# ATSAMD21E15BU register map
Vendor: Atmel Corporation; Series: SAMD21; File version: D
CPU: CM0+ r0p1, little endian, no MPU, no FPU, VTOR, 2 interrupt priority bits
Registers are 8-bit, read-write, reset 0x0 unless marked. A register's access mark holds for its fields unless they carry their own. Offsets are from the block's base; [hi:lo] are bit positions; {n}, {i} and the like mark numbered series; 'fields as' and 'values as' point back to an identical list.

## DAC — Digital Analog Converter
Base 0x42004800; register names take the prefix DAC_
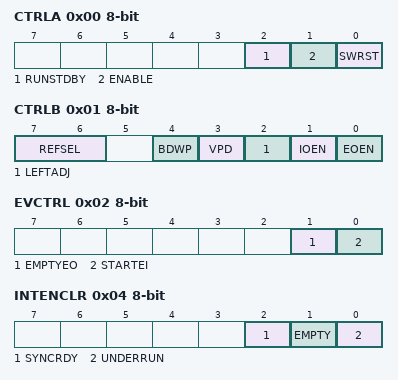
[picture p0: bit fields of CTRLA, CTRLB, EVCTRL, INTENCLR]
0x00 CTRLA — Control A
  [2] RUNSTDBY — Run in Standby
  [1] ENABLE
  [0] SWRST — Software Reset
0x01 CTRLB — Control B
  [7:6] REFSEL — Reference Selection
    0=INT1V (Internal 1.0V reference); 1=AVCC; 2=VREFP (External reference)
  [4] BDWP — Bypass DATABUF Write Protection
  [3] VPD — Voltage Pump Disable
  [2] LEFTADJ — Left Adjusted Data
  [1] IOEN — Internal Output Enable
  [0] EOEN — External Output Enable
0x02 EVCTRL — Event Control
  [1] EMPTYEO — Data Buffer Empty Event Output
  [0] STARTEI — Start Conversion Event Input
0x04 INTENCLR — Interrupt Enable Clear
  [2] SYNCRDY — Synchronization Ready Interrupt Enable
  [1] EMPTY — Data Buffer Empty Interrupt Enable
  [0] UNDERRUN — Underrun Interrupt Enable
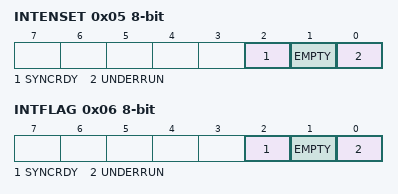
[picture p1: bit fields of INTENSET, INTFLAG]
0x05 INTENSET — Interrupt Enable Set
  fields as INTENCLR
0x06 INTFLAG — Interrupt Flag Status and Clear
  [2] SYNCRDY — Synchronization Ready
  [1] EMPTY — Data Buffer Empty
  [0] UNDERRUN
0x07 STATUS ro
  [7] SYNCBUSY — Synchronization Busy Status
0x08 DATA 16-bit
  [15:0] DATA — Data value to be converted
0x0C DATABUF 16-bit — Data Buffer

## DSU — Device Service Unit
Base 0x41002000; register names take the prefix DSU_
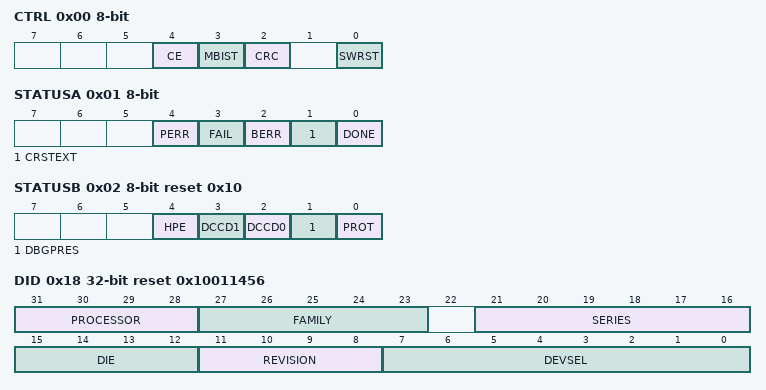
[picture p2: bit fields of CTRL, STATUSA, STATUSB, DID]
0x00 CTRL wo — Control
  [4] CE — Chip Erase
  [3] MBIST — Memory Built-In Self-Test
  [2] CRC — 32-bit Cyclic Redundancy Check
  [0] SWRST — Software Reset
0x01 STATUSA
  [4] PERR — Protection Error
  [3] FAIL — Failure
  [2] BERR — Bus Error
  [1] CRSTEXT — CPU Reset Phase Extension
  [0] DONE
0x02 STATUSB ro reset 0x10
  [4] HPE — Hot-Plugging Enable
  [3] DCCD1 — Debug Communication Channel 1 Dirty
  [2] DCCD0 — Debug Communication Channel 0 Dirty
  [1] DBGPRES — Debugger Present
  [0] PROT — Protected
0x04 ADDR 32-bit — Address
  [31:2] ADDR
0x08 LENGTH 32-bit
  [31:2] LENGTH
0x0C DATA 32-bit
{0x10+4i} DCC{i} (i=0..1) 32-bit — Debug Communication Channel n
  [31:0] DATA
0x18 DID 32-bit ro reset 0x10011456 — Device Identification
  [31:28] PROCESSOR
  [27:23] FAMILY — Product Family
  [21:16] SERIES — Product Series
  [15:12] DIE — Die Identification
  [11:8] REVISION
  [7:0] DEVSEL — Device Select
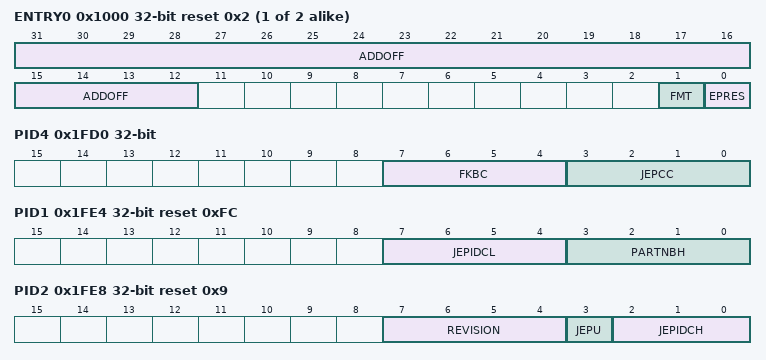
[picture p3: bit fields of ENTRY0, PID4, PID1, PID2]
{0x1000+4i} ENTRY{i} (i=0..1) 32-bit ro reset 0x2 — Coresight ROM Table Entry n
  [31:12] ADDOFF — Address Offset
  [1] FMT — Format
  [0] EPRES — Entry Present
0x1008 END 32-bit ro — Coresight ROM Table End
  [31:0] END — End Marker
0x1FCC MEMTYPE 32-bit ro — Coresight ROM Table Memory Type
  [0] SMEMP — System Memory Present
0x1FD0 PID4 32-bit ro — Peripheral Identification 4
  [7:4] FKBC — 4KB Count
  [3:0] JEPCC — JEP-106 Continuation Code
0x1FE0 PID0 32-bit ro reset 0xD0 — Peripheral Identification 0
  [7:0] PARTNBL — Part Number Low
0x1FE4 PID1 32-bit ro reset 0xFC — Peripheral Identification 1
  [7:4] JEPIDCL — Low part of the JEP-106 Identity Code
  [3:0] PARTNBH — Part Number High
0x1FE8 PID2 32-bit ro reset 0x9 — Peripheral Identification 2
  [7:4] REVISION — Revision Number
  [3] JEPU — JEP-106 Identity Code is used
  [2:0] JEPIDCH — JEP-106 Identity Code High
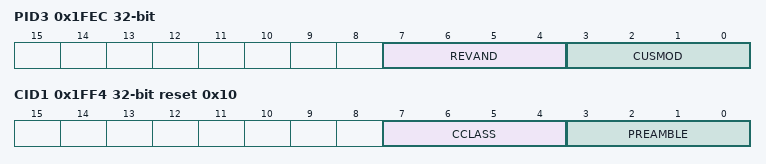
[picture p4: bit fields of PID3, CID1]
0x1FEC PID3 32-bit ro — Peripheral Identification 3
  [7:4] REVAND — Revision Number
  [3:0] CUSMOD — ARM CUSMOD
0x1FF0 CID0 32-bit ro reset 0xD — Component Identification 0
  [7:0] PREAMBLEB0 — Preamble Byte 0
0x1FF4 CID1 32-bit ro reset 0x10 — Component Identification 1
  [7:4] CCLASS — Component Class
  [3:0] PREAMBLE
0x1FF8 CID2 32-bit ro reset 0x5 — Component Identification 2
  [7:0] PREAMBLEB2 — Preamble Byte 2
0x1FFC CID3 32-bit ro reset 0xB1 — Component Identification 3
  [7:0] PREAMBLEB3 — Preamble Byte 3

## EIC — External Interrupt Controller
Base 0x40001800; register names take the prefix EIC_
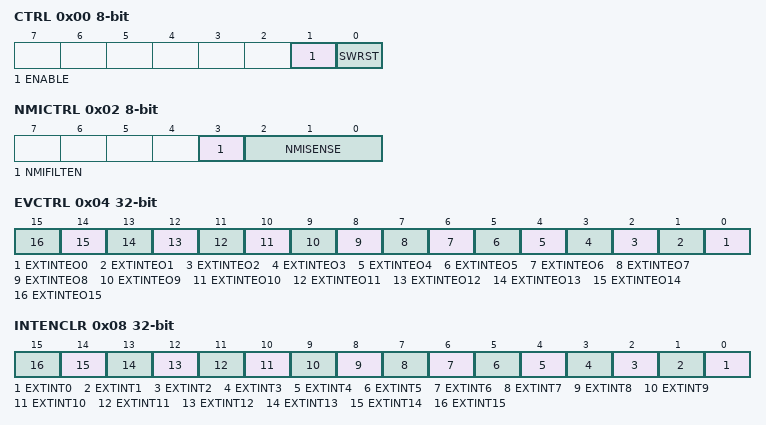
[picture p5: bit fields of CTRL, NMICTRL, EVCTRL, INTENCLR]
0x00 CTRL — Control
  [1] ENABLE
  [0] SWRST — Software Reset
0x01 STATUS ro
  [7] SYNCBUSY — Synchronization Busy
0x02 NMICTRL — Non-Maskable Interrupt Control
  [3] NMIFILTEN — Non-Maskable Interrupt Filter Enable
  [2:0] NMISENSE — Non-Maskable Interrupt Sense
    0=NONE (No detection); 1=RISE (Rising-edge detection); 2=FALL (Falling-edge detection); 3=BOTH (Both-edges detection); 4=HIGH (High-level detection); 5=LOW (Low-level detection)
0x03 NMIFLAG — Non-Maskable Interrupt Flag Status and Clear
  [0] NMI — Non-Maskable Interrupt
0x04 EVCTRL 32-bit — Event Control
  [n] EXTINTEO{n} (n=0..15) — External Interrupt {n} Event Output Enable
0x08 INTENCLR 32-bit — Interrupt Enable Clear
  [n] EXTINT{n} (n=0..15) — External Interrupt {n} Enable
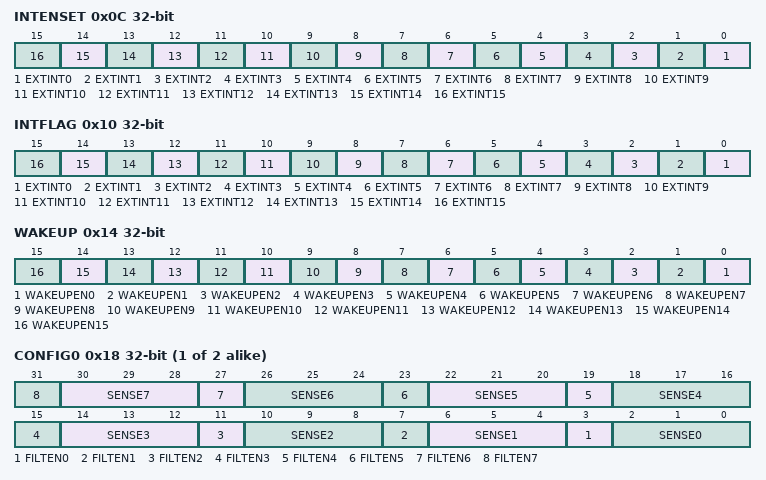
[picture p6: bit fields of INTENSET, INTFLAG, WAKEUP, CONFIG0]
0x0C INTENSET 32-bit — Interrupt Enable Set
  [n] EXTINT{n} (n=0..15) — External Interrupt {n} Enable
0x10 INTFLAG 32-bit — Interrupt Flag Status and Clear
  [n] EXTINT{n} (n=0..15) — External Interrupt {n}
0x14 WAKEUP 32-bit — Wake-Up Enable
  [n] WAKEUPEN{n} (n=0..15) — External Interrupt {n} Wake-up Enable
{0x18+4i} CONFIG{i} (i=0..1) 32-bit — Configuration n
  [4n+3] FILTEN{n} (n=0..7) — Filter {n} Enable
  [4n+2:4n] SENSE{n} (n=1..7) — Input Sense {n} Configuration
    0=NONE (No detection); 1=RISE (Rising edge detection); 2=FALL (Falling edge detection); 3=BOTH (Both edges detection); 4=HIGH (High level detection); 5=LOW (Low level detection)
  [2:0] SENSE0 — Input Sense 0 Configuration
    values as NMICTRL.NMISENSE

## Notices in the file
Atmel Microcontroller Software Support
Copyright (c) 2016 Atmel Corporation,
a wholly owned subsidiary of Microchip Technology Inc.
Licensed under the Apache License, Version 2.0 (the "License");
you may not use this file except in compliance with the License.
You may obtain a copy of the Licence at
http://www.apache.org/licenses/LICENSE-2.0
Unless required by applicable law or agreed to in writing, software
distributed under the License is distributed on an "AS IS" BASIS,
WITHOUT WARRANTIES OR CONDITIONS OF ANY KIND, either express or implied.
See the License for the specific language governing permissions and
limitations under the License.
